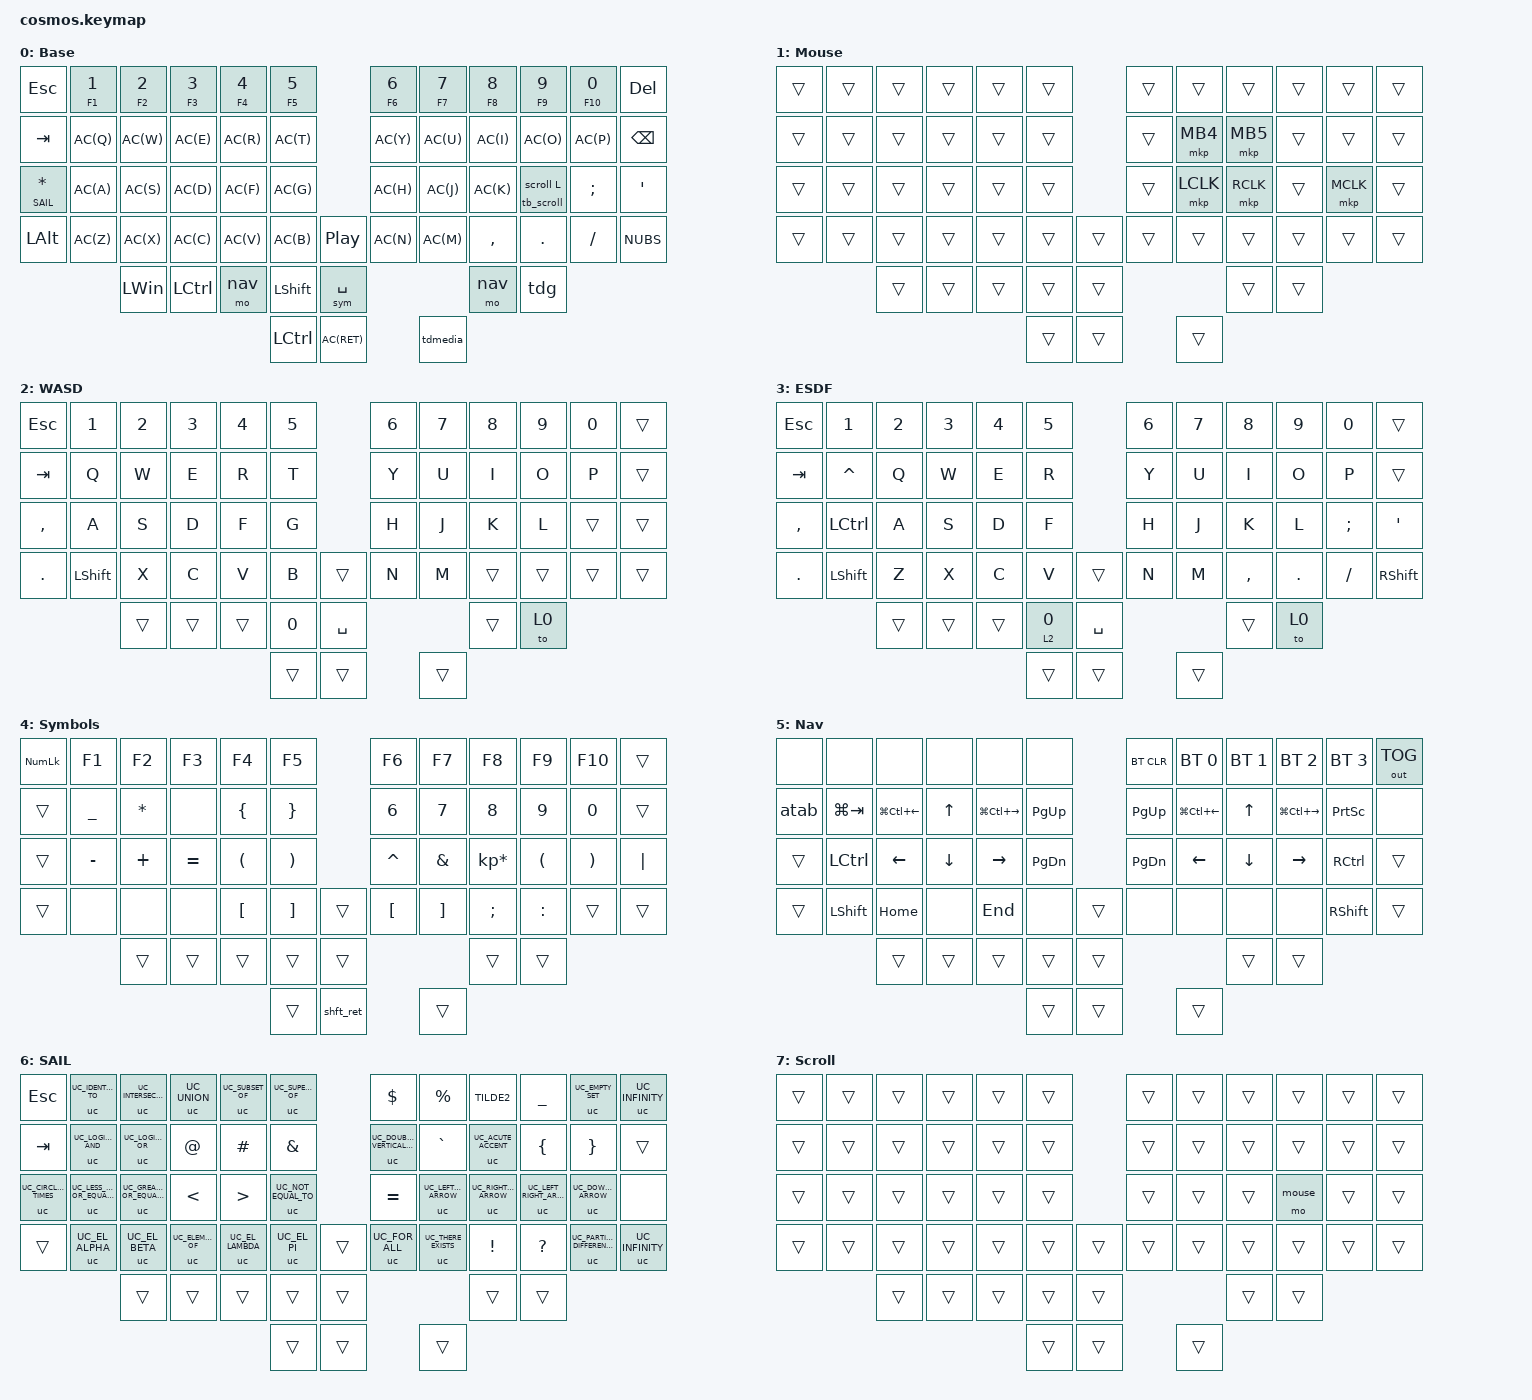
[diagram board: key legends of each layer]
/*
 * Copyright (c) 2020 The ZMK Contributors
 *
 * SPDX-License-Identifier: MIT
 */

#include <dt-bindings/zmk/mouse.h>
#include <behaviors.dtsi>
#include <dt-bindings/zmk/keys.h>
#include <dt-bindings/zmk/bt.h>
#include <dt-bindings/zmk/outputs.h>
#include <behaviors/unicode.dtsi>

// #define ZMK_POINTING_DEFAULT_MOVE_VAL 600  // default: 600
// #define ZMK_POINTING_DEFAULT_SCRL_VAL 140    // default: 10
#include <dt-bindings/zmk/pointing.h>
#include <zmk-unicode/keys-extra.h>

#include "cosmos_behaviors.dtsi"

//Layers
#define default 0
#define mouse 1
#define wasd 2
#define esdf 3
#define sym 4
#define nav 5
#define SAIL 6
#define scroll 7


#define MEH(key) LS(LC(LA(key)))
#define AC(keycode) &ht LC(keycode) keycode     // Autoctrl Macro
#define AS(keycode) &ht LS(keycode) keycode     // Autoshift Macro

// Layer-specific behavior (references keymap layer names)

/ {
	behaviors {
		tdg: tap_dance_gaming_layers {
			compatible = "zmk,behavior-tap-dance";
			label = "TAP_DANCE_GAMING_LAYERS";
			#binding-cells = <0>;
			tapping-term-ms = <200>;
			bindings = <&to esdf>, <&to wasd>;
		};
	};
};

/ {
	keymap {
		compatible = "zmk,keymap";

		default_layer {
			display-name = "Base";   
// ------------------------------------------------------------------------------------------------------------
// |  ESC  |  1  |  2  |  3   |  4   |  5   |                   |  6   |  7    |  8    |  9   |   0   |  DEL  |
// |  TAB  |  Q  |  W  |  E   |  R   |  T   |                   |  Y   |  U    |  I    |  O   |   P   | BKSPC |
// |  SAIL |  A  |  S  |  D   |  F   |  G   |                   |  H   |  J    |  K    |  L   |   ;   |   '   |
// |  ALT  |  Z  |  X  |  C   |  V   |  B   |  MEDIA |          |  N   |  M    |  ,    |  .   |   /   |   \   |
//               | GUI |RAISE | NAV  | SHIFT|  SPACE |                         | NAV   | Game |

			bindings = <
&kp ESC       &ht F1 N1 &ht F2 N2 &ht F3 N3  &ht F4 N4 &ht F5 N5                            &ht F6 N6    &ht F7 N7 &ht F8 N8  &ht F9 N9           &ht F10 N0 &kp DEL 
&kp TAB       AC(Q)     AC(W)     AC(E)     AC(R)      AC(T)                                AC(Y)        AC(U)     AC(I)      AC(O)               AC(P)      &kp BSPC
&lt SAIL STAR AC(A)     AC(S)     AC(D)     AC(F)      AC(G)                                AC(H)        AC(J)     AC(K)      &tb_scroll scroll L &kp SEMI   &kp SQT
&kp LALT      AC(Z)     AC(X)     AC(C)     AC(V)      AC(B)   &kp C_PLAY_PAUSE             AC(N)        AC(M)     &kp COMMA  &kp DOT             &kp FSLH   &kp NUBS
						&kp LWIN  &kp LCTRL &mo nav    &kp LSHFT  &lt sym SPACE                                    &mo nav    &tdg
													   &kp LCTRL  AC(RET)                                     &tdmedia
			>;

			sensor-bindings = <&inc_dec_kp C_VOL_UP C_VOL_DN &scroll_up_down>;
		};

		mouse_layer {
			display-name = "Mouse";   
			bindings = <
&trans  &trans    &trans   &trans    &trans    &trans                      &trans  &trans    &trans    &trans    &trans    &trans
&trans  &trans    &trans   &trans    &trans    &trans                      &trans  &mkp MB4  &mkp MB5  &trans    &trans    &trans
&trans  &trans    &trans   &trans    &trans    &trans                      &trans  &mkp LCLK &mkp RCLK &trans    &mkp MCLK &trans
&trans  &trans    &trans   &trans    &trans    &trans   &trans             &trans  &trans    &trans    &trans    &trans    &trans
				  &trans   &trans       &trans    &trans   &trans                                      &trans    &trans
												  &trans   &trans                                   &trans
			>;

			sensor-bindings = <&inc_dec_kp C_VOL_UP C_VOL_DN &scroll_up_down>;
		};

		
		wasd_layer {
			display-name = "WASD";   
			bindings = <
&kp ESC   &kp N1    &kp N2   &kp N3    &kp N4    &kp N5                      &kp N6  &kp N7    &kp N8    &kp N9    &kp N0   &trans
&kp TAB   &kp Q     &kp W    &kp E     &kp R     &kp T                       &kp Y   &kp U     &kp I     &kp O     &kp P    &trans
&kp COMMA &kp A     &kp S    &kp D     &kp F     &kp G                       &kp H   &kp J     &kp K     &kp L     &trans   &trans
&kp DOT   &kp LSHFT &kp X    &kp C     &kp V     &kp B    &trans             &kp N   &kp M     &trans    &trans    &trans   &trans
					&trans   &trans    &trans    &kp N0   &kp SPACE                            &trans    &to 0
												 &trans   &trans                          &trans
			>;

			sensor-bindings = <&inc_dec_kp C_VOL_UP C_VOL_DN &scroll_up_down>;
		};
		
		
		esdf_layer {
			display-name = "ESDF";   
			bindings = <
&kp ESC   &kp N1    &kp N2   &kp N3   &kp N4    &kp N5                          &kp N6  &kp N7    &kp N8    &kp N9    &kp N0   &trans
&kp TAB   &kp CARET &kp Q    &kp W    &kp E     &kp R                           &kp Y   &kp U     &kp I     &kp O     &kp P    &trans
&kp COMMA &kp LCTRL &kp A    &kp S    &kp D     &kp F                           &kp H   &kp J     &kp K     &kp L     &kp SEMI &kp SQT
&kp DOT   &kp LSHFT &kp Z    &kp X    &kp C     &kp V     &trans                &kp N   &kp M     &kp COMMA &kp DOT   &kp FSLH &kp RSHFT
					&trans   &trans   &trans    &lt 2 N0  &kp SPACE                               &trans    &to 0
												&trans    &trans                             &trans

			>;

			sensor-bindings = <&inc_dec_kp C_VOL_UP C_VOL_DN &scroll_up_down>;
		};


		sym_layer {
			display-name = "Symbols";   
// ------------------------------------------------------------------------------------------------------------
// | NUM |  F1 |  F2 |  F3  |  F4  |  F5  |                   |  F6  |  F7   |  F8   |  F9  |  F10  |  F11  |
// |     |  _  |  *  |      |  {   |   }  |                   |   6  |   7   |   8   |   9  |    0  |  F12  |
// |     |  -  |  +  |  =   |  (   |  )   |                   |  ^   |  &    |  *    |  (   |   )   |   |   |
// |     |     |     |      |  [   |  ]   |      |            |  [   |  ]    |  ;    |  :   |   \   |       |
//             |     |      |      |      |      |                           |       |      |
//                                 |      |      |    

			bindings = <
&kp KP_NUM  &kp F1    &kp F2    &kp F3      &kp F4    &kp F5                     &kp F6    &kp F7   &kp F8          &kp F9    &kp F10   &trans
&trans      &kp UNDER &kp STAR  &none       &kp LBRC  &kp RBRC                   &kp N6    &kp N7   &kp N8          &kp N9    &kp N0    &trans
&trans      &kp MINUS &kp PLUS  &kp EQUAL   &kp LPAR  &kp RPAR                   &kp CARET &kp AMPS &kp KP_MULTIPLY &kp LPAR  &kp RPAR  &kp PIPE
&trans      &none     &none     &none       &kp LBKT  &kp RBKT   &trans          &kp LBKT  &kp RBKT &kp SEMI        &kp COLON &trans    &trans
					  &trans    &trans      &trans    &trans     &trans                             &trans          &trans
													  &trans     &shft_ret                        &trans

			>;

			sensor-bindings = <&inc_dec_kp C_VOL_UP C_VOL_DN &scroll_up_down>;
		};



		nav_layer {
			display-name = "Nav";   
// ------------------------------------------------------------------------------------------------------------
// |     |      |      |       |       |      |                |BTCLR | BT1  |  BT2  |  BT3  |  BT4  |  BT5  |
// |     |      | WIN← |   ↑   |  WIN→ | PGUP |                | PGUP | WIN← |   ↑   |  WIN→ |       |       |
// |SHIFT| SHIFT|   ←  |   ↓   |   →   | PGDN |                | PGDN |   ←  |   ↓   |   →   | CTRL  |       |
// |     | CTRL | HOME |       |  END  |      |      |                       |       |       | SHIFT |       |
//              |      |       |       |      |      |                       |       |       |

			bindings = <
&none      &none       &none            &none    &none             &none                       &bt BT_CLR &bt BT_SEL 0     &bt BT_SEL 1 &bt BT_SEL 2      &bt BT_SEL 3  &out OUT_TOG
&atab      &kp LG(TAB) &kp LG(LC(LEFT)) &kp UP   &kp LG(LC(RIGHT)) &kp PG_UP                   &kp PG_UP  &kp LG(LC(LEFT)) &kp UP       &kp LG(LC(RIGHT)) &kp PSCRN     &none
&trans     &kp LCTRL   &kp LEFT         &kp DOWN &kp RIGHT         &kp PG_DN                   &kp PG_DN  &kp LEFT         &kp DOWN     &kp RIGHT         &kp RCTRL     &trans
&trans     &kp LSHIFT  &kp HOME         &none    &kp END           &none      &trans           &none      &none            &none        &none             &kp RSHFT     &trans
					  &trans           &trans   &trans            &trans     &trans                                       &trans       &trans
																  &trans     &trans                                    &trans
			>;

			sensor-bindings = <&inc_dec_kp C_VOL_UP C_VOL_DN &scroll_up_down>;
		};
		
		
		
		sail_layer {
			display-name = "SAIL";   
// ------------------------------------------------------------------------------------------------------------
// | ESC |  ≡   |   ∩  |   ∪   |   ⊂  |   ⊃  |                |   $   |   %   |   ~   |   _   |       |   ∞   |
// | TAB |  ≤   |   ≥  |   @   |   #   |   &  |                |   ‖   |   `   |   ´   |   {   |   }   |   BS  |
// |  ⊗ |  ≤   |   ≥  |   <   |   >   |   ≠  |                |   =   |   ←   |   →   |   ↔   |   ↓   |       |
// | ALT |   α  |   β  |   ε   |   λ   |   π  |                |   ∀   |   ∃   |   !   |   ?   |   ∂   |   ∞   |
//              | META | RAISE | LOWER | SHIFT|      |                         |  LEFT | RIGHT |
//                                     | CTRL |  RET |                     |      |
bindings = <
&kp ESC              &uc UC_IDENTICAL_TO          &uc UC_INTERSECTION             &uc UC_UNION      &uc UC_SUBSET_OF &uc UC_SUPERSET_OF               &kp DLLR                    &kp PRCNT              &kp TILDE2              &kp UNDER               &uc UC_EMPTY_SET            &uc UC_INFINITY 
&kp TAB              &uc UC_LOGICAL_AND           &uc UC_LOGICAL_OR               &kp AT_SIGN       &kp HASH         &kp AMPS                         &uc UC_DOUBLE_VERTICAL_LINE &kp GRAVE              &uc UC_ACUTE_ACCENT     &kp LBRC                &kp RBRC                    &trans
&uc UC_CIRCLED_TIMES &uc UC_LESS_THAN_OR_EQUAL_TO &uc UC_GREATER_THAN_OR_EQUAL_TO &kp LESS_THAN     &kp GREATER_THAN &uc UC_NOT_EQUAL_TO              &kp EQUAL                   &uc UC_LEFTWARDS_ARROW &uc UC_RIGHTWARDS_ARROW &uc UC_LEFT_RIGHT_ARROW &uc UC_DOWNWARDS_ARROW      &none    
&trans               &uc UC_EL_ALPHA              &uc UC_EL_BETA                  &uc UC_ELEMENT_OF &uc UC_EL_LAMBDA &uc UC_EL_PI        &trans       &uc UC_FOR_ALL              &uc UC_THERE_EXISTS    &kp EXCLAMATION         &kp QUESTION            &uc UC_PARTIAL_DIFFERENTIAL &uc UC_INFINITY 
												  &trans                          &trans            &trans           &trans              &trans                                                          &trans                  &trans 
																													&trans              &trans                                                    &trans

			>;

			sensor-bindings = <&inc_dec_kp C_VOL_UP C_VOL_DN &scroll_up_down>;
		};
		
		scroll_layer {
			display-name = "Scroll";
			bindings = <
&trans  &trans    &trans   &trans    &trans    &trans                      &trans  &trans    &trans    &trans    &trans    &trans
&trans  &trans    &trans   &trans    &trans    &trans                      &trans  &trans    &trans    &trans    &trans    &trans
&trans  &trans    &trans   &trans    &trans    &trans                      &trans  &trans    &trans    &mo mouse &trans    &trans
&trans  &trans    &trans   &trans    &trans    &trans   &trans             &trans  &trans    &trans    &trans    &trans    &trans
				  &trans   &trans       &trans    &trans   &trans                                      &trans    &trans
												  &trans   &trans                                   &trans
			>;

			sensor-bindings = <&inc_dec_kp C_VOL_UP C_VOL_DN &scroll_up_down>;
		};
	};
};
